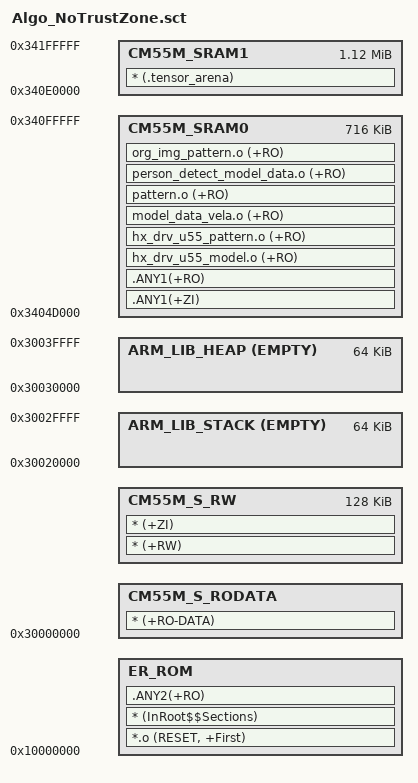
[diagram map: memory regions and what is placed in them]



/*--------------------- Flash Configuration ----------------------------------*/
#define CM55M_ROM_BASE     0x10000000
#define CM55M_ROM_SIZE     0x00040000

/*--------------------- Embedded RAM Configuration ---------------------------*/
#define CM55M_DATA_BASE     0x30000000
#define CM55M_DATA_SIZE     0x00040000

#define CM55M_SRAM_BASE     0x34000000
#define CM55M_SRAM0_SIZE    0x00100000
#define CM55M_SRAM1_BASE     0x340E0000
#define CM55M_SRAM1_SIZE    0x00120000
/*--------------------- Stack / Heap Configuration ---------------------------*/
#define __STACK_SIZE    0x00010000
#define __HEAP_SIZE     0x00010000
#define CM55M_APP_DATASECT_SIZE  (CM55M_DATA_SIZE - __STACK_SIZE - __HEAP_SIZE)
#define CM55M_APP_SRAMSECT_SIZE  (CM55M_SRAM0_SIZE - __STACK_SIZE - __HEAP_SIZE)
#define EXTRA_BASE     CM55M_DATA_BASE
#define EXTRA_SIZE     CM55M_APP_DATASECT_SIZE
#define __STACK_LIMIT   (EXTRA_BASE + EXTRA_SIZE)
#define __STACK_BASE    (EXTRA_BASE + EXTRA_SIZE + __STACK_SIZE)
#define __HEAP_BASE     (EXTRA_BASE + EXTRA_SIZE + __STACK_SIZE)
#define __HEAP_LIMIT    (EXTRA_BASE + EXTRA_SIZE + __STACK_SIZE + __HEAP_SIZE)


LR_ROM1 CM55M_ROM_BASE CM55M_ROM_SIZE  {                       
  ER_ROM +0 {                                       
   *.o (RESET, +First)
   * (InRoot$$Sections)
   .ANY2(+RO)
  }
}

LR_ROM2 CM55M_DATA_BASE  CM55M_DATA_SIZE{   
  CM55M_S_RODATA  +0 { 
   * (+RO-DATA)
  }	 
  CM55M_S_RW +0 CM55M_APP_DATASECT_SIZE{    
   * (+RW)
   * (+ZI)

  }


  ARM_LIB_STACK __STACK_BASE ALIGN 8 EMPTY -__STACK_SIZE {  
  }
  
  ARM_LIB_HEAP  __HEAP_BASE ALIGN 8 EMPTY __HEAP_SIZE  { 
  }
}

LR_ROM3 CM55M_SRAM_BASE CM55M_SRAM0_SIZE {
  CM55M_SRAM0 +0x4D000 CM55M_SRAM0_SIZE-0x4D000{
  /*CM55M_SRAM0 +0 CM55M_SRAM0_SIZE{*/                                       
   .ANY1(+ZI)
   .ANY1(+RO)
   hx_drv_u55_model.o (+RO)
   hx_drv_u55_pattern.o (+RO)
   model_data_vela.o (+RO)
   pattern.o (+RO)
   person_detect_model_data.o (+RO)
   org_img_pattern.o (+RO)
   
  }

}

LR_ROM4 CM55M_SRAM1_BASE CM55M_SRAM1_SIZE {
  CM55M_SRAM1 +0 CM55M_SRAM1_SIZE{
  	* (.tensor_arena)
  }

}


